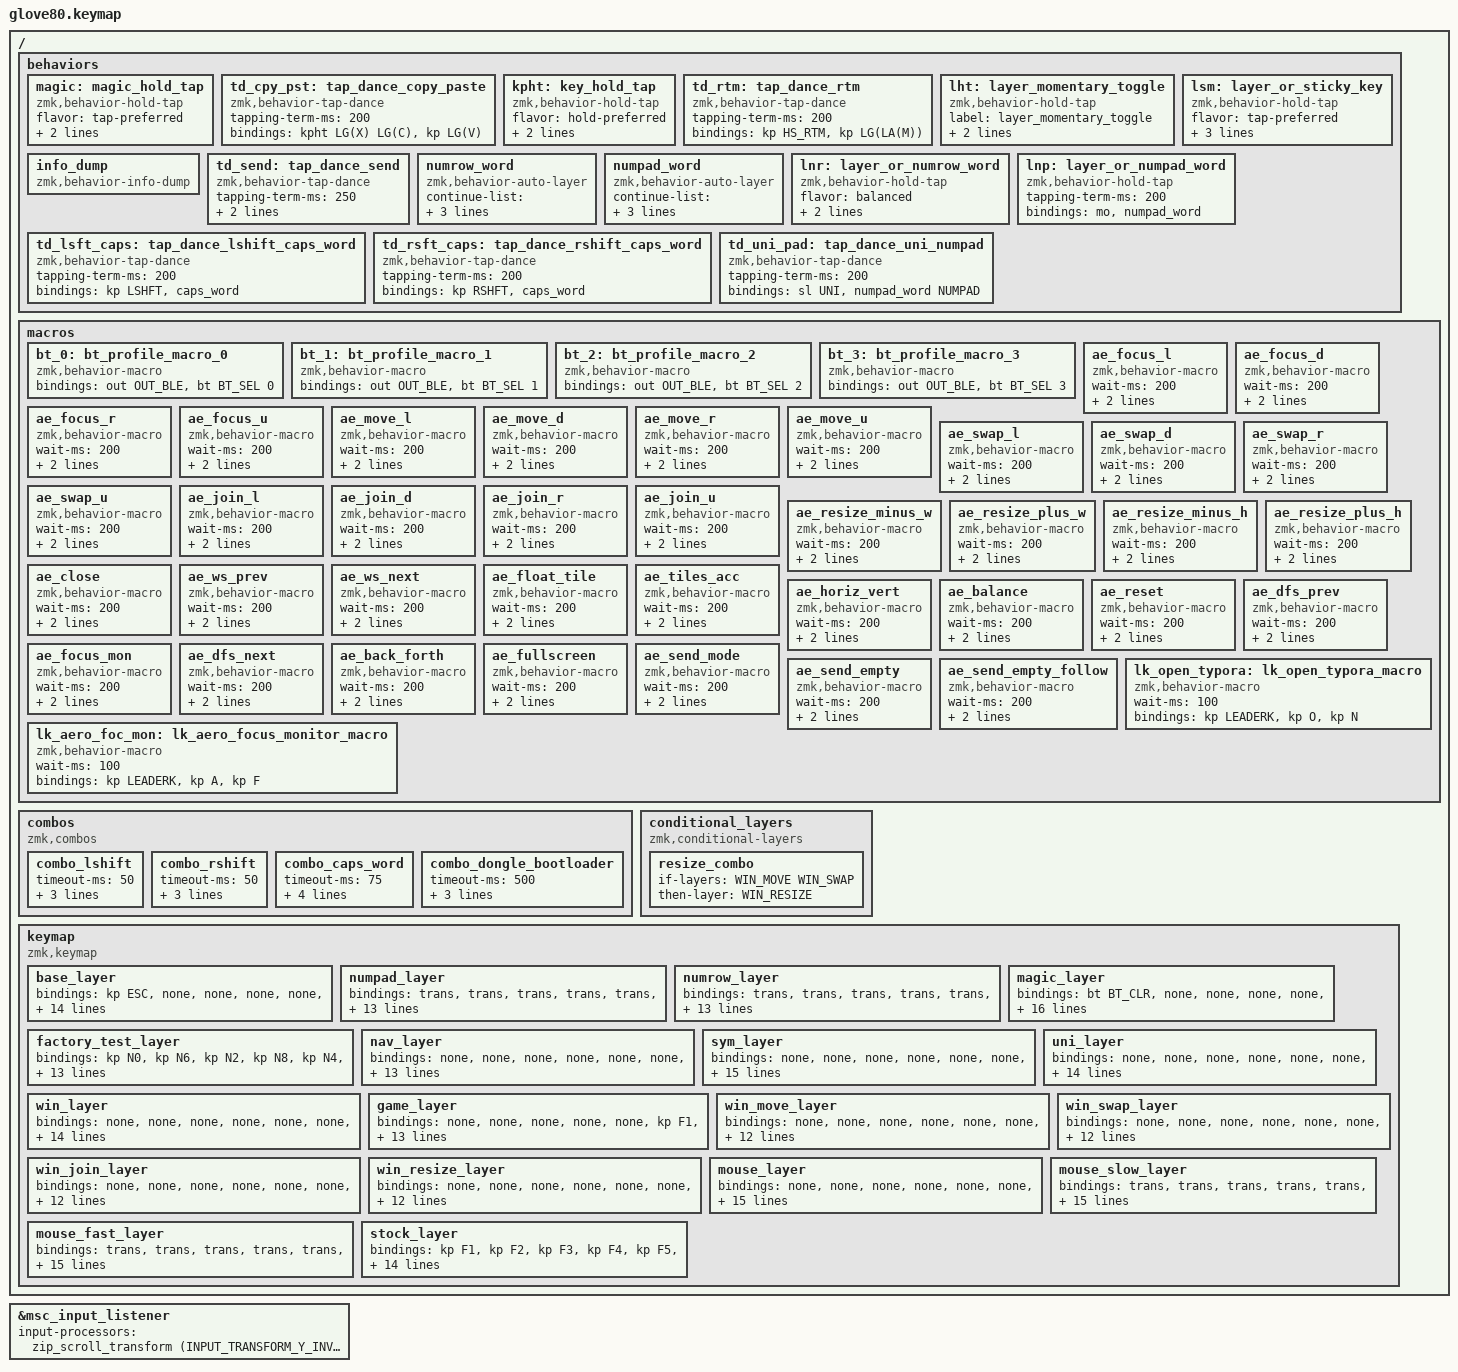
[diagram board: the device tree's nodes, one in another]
/*
 * Copyright (c) 2020 The ZMK Contributors
 *
 * SPDX-License-Identifier: MIT
 */

#include <dt-bindings/zmk/mouse.h>
#include <dt-bindings/zmk/input_transform.h>
#include <input/processors.dtsi>
#include <behaviors.dtsi>
#include <dt-bindings/zmk/bt.h>
#include <dt-bindings/zmk/keys.h>
#include <dt-bindings/zmk/outputs.h>
#include <dt-bindings/zmk/pointing.h>
#include <dt-bindings/zmk/rgb.h>

#define HYPER(X) LC(LS(LG(LA(X))))

// Layers

#define BASE         0
#define NUMPAD       1
#define NUMROW       2
#define MAGIC        3
#define TEST         4
#define NAV          5
#define SYM          6
#define UNI          7
#define WIN          8
#define GAME         9
#define WIN_MOVE     10
#define WIN_SWAP     11
#define WIN_JOIN     12
#define WIN_RESIZE   13
#define MOUSE        14
#define MOUSE_SLOW   15
#define MOUSE_FAST   16
#define STOCK        17

// Hammerspoon Hyper-key triggers (HYPER is defined in glove80.keymap)

#define HS_WARP HYPER(A) // Launch warpd
#define HS_CHRM HYPER(B) // Launch Chrome
#define HS_MEET HYPER(C) // Launch Meet
#define HS_TYPR HYPER(D) // Launch Typora
#define HS_SLAK HYPER(E) // Launch Slack
#define HS_CODE HYPER(F) // Launch VS Code
#define HS_PTAB HYPER(G) // Previous Tab
#define HS_NTAB HYPER(H) // Next Tab
#define HS_SCRN HYPER(I) // Switch Monitor Focus
#define HS_TERM HYPER(J) // Launch iTerm2
#define HS_RTM  HYPER(K) // Launch Remember the Milk
#define HS_SPFY HYPER(L) // Launch Spotify
#define HS_SCDN HYPER(M) // Scroll Down
#define HS_SCUP HYPER(N) // Scroll Up
#define HS_BTN1 HYPER(O) // Click Mouse Button 1
#define HS_MCTR HYPER(P) // Move mouse to center of screen
#define HS_MENU HYPER(Q) // Open interactive hammerspoon menu system
#define HS_TSCR HYPER(R) // Trackball scroll mode
#define LEADERK HYPER(S) // Open Leader Key
#define HS_TNEW HYPER(T) // New Tab
#define SHRTCAT HYPER(U) // Shortcat.app
#define HRCLICK HYPER(V) // Homerow.app click mode
#define HRSCRLL HYPER(W) // Homerow.app scroll mode

// Magnet.app

#define MAG_L   LC(LA(LEFT))
#define MAG_R   LC(LA(RIGHT))
#define MAG_MAX LC(LA(ENTER))
#define MAG_RST LC(LA(BSPC))

// Aerospace.app — hyper chord triggers action mode; macros append the verb key

#define AE_CHORD HYPER(SPACE)

// Mouse speed overlay macros — hold E (slow) or R (fast) while scrolling/moving

#define SCRL_UP_LO    MOVE_Y(ZMK_POINTING_DEFAULT_SCRL_VAL / 3)
#define SCRL_DOWN_LO  MOVE_Y(-(ZMK_POINTING_DEFAULT_SCRL_VAL / 3))
#define SCRL_LEFT_LO  MOVE_X(-(ZMK_POINTING_DEFAULT_SCRL_VAL / 3))
#define SCRL_RIGHT_LO MOVE_X(ZMK_POINTING_DEFAULT_SCRL_VAL / 3)
#define SCRL_UP_HI    MOVE_Y(ZMK_POINTING_DEFAULT_SCRL_VAL * 3)
#define SCRL_DOWN_HI  MOVE_Y(-(ZMK_POINTING_DEFAULT_SCRL_VAL * 3))
#define SCRL_LEFT_HI  MOVE_X(-(ZMK_POINTING_DEFAULT_SCRL_VAL * 3))
#define SCRL_RIGHT_HI MOVE_X(ZMK_POINTING_DEFAULT_SCRL_VAL * 3)
#define MOVE_UP_LO    MOVE_Y(-(ZMK_POINTING_DEFAULT_MOVE_VAL / 3))
#define MOVE_DOWN_LO  MOVE_Y(ZMK_POINTING_DEFAULT_MOVE_VAL / 3)
#define MOVE_LEFT_LO  MOVE_X(-(ZMK_POINTING_DEFAULT_MOVE_VAL / 3))
#define MOVE_RIGHT_LO MOVE_X(ZMK_POINTING_DEFAULT_MOVE_VAL / 3)
#define MOVE_UP_HI    MOVE_Y(-(ZMK_POINTING_DEFAULT_MOVE_VAL * 3))
#define MOVE_DOWN_HI  MOVE_Y(ZMK_POINTING_DEFAULT_MOVE_VAL * 3)
#define MOVE_LEFT_HI  MOVE_X(-(ZMK_POINTING_DEFAULT_MOVE_VAL * 3))
#define MOVE_RIGHT_HI MOVE_X(ZMK_POINTING_DEFAULT_MOVE_VAL * 3)

// WIN layer LH home-row hold-taps: hold=sublayer, tap=sticky mod

#define SK_PINKY lsm 0 LCTRL
#define SK_JOIN  lsm WIN_JOIN LALT
#define SK_SWAP  lsm WIN_SWAP LGUI
#define SK_MOVE  lsm WIN_MOVE LSHFT

/ {
    behaviors {
        magic: magic_hold_tap {
            compatible = "zmk,behavior-hold-tap";
            #binding-cells = <2>;
            flavor = "tap-preferred";
            tapping-term-ms = <200>;
            bindings = <&mo>, <&none>;
        };

        td_cpy_pst: tap_dance_copy_paste {
            compatible = "zmk,behavior-tap-dance";
            #binding-cells = <0>;
            tapping-term-ms = <200>;
            bindings = <&kpht LG(X) LG(C)>, <&kp LG(V)>;
        };

        kpht: key_hold_tap {
            compatible = "zmk,behavior-hold-tap";
            #binding-cells = <2>;
            flavor = "hold-preferred";
            tapping-term-ms = <500>;
            bindings = <&kp>, <&kp>;
        };

        td_rtm: tap_dance_rtm {
            compatible = "zmk,behavior-tap-dance";
            #binding-cells = <0>;
            tapping-term-ms = <200>;
            bindings = <&kp HS_RTM>, <&kp LG(LA(M))>;
        };

        lht: layer_momentary_toggle {
            compatible = "zmk,behavior-hold-tap";
            label = "layer_momentary_toggle";
            bindings = <&mo>, <&tog>;

            #binding-cells = <2>;
            tapping-term-ms = <200>;
        };

        lsm: layer_or_sticky_key {
            compatible = "zmk,behavior-hold-tap";
            #binding-cells = <2>;
            flavor = "tap-preferred";
            tapping-term-ms = <200>;
            quick-tap-ms = <100>;
            bindings = <&mo>, <&sk>;
        };

        info_dump: info_dump {
            compatible = "zmk,behavior-info-dump";
            #binding-cells = <0>;
        };

        td_send: tap_dance_send {
            compatible = "zmk,behavior-tap-dance";
            #binding-cells = <0>;
            tapping-term-ms = <250>;
            bindings =
                <&ae_send_mode>,
                <&ae_send_empty>,
                <&ae_send_empty_follow>;
        };

        // Auto-layers (urob/zmk-auto-layer): the layer stays active while typing
        // digits and the continue-list keys, and deactivates on any other keycode.
        // Tapping the trigger again also deactivates. Two instances so NUMROW and
        // NUMPAD keep independent on/off state.

        numrow_word: numrow_word {
            compatible = "zmk,behavior-auto-layer";
            #binding-cells = <1>;
            continue-list = <BSPC DEL DOT COMMA PLUS MINUS STAR FSLH EQUAL COLON>;
            ignore-numbers;
            ignore-modifiers; // home-row mods inside the layer must not end number mode
        };

        numpad_word: numpad_word {
            compatible = "zmk,behavior-auto-layer";
            #binding-cells = <1>;
            continue-list = <BSPC DEL DOT COMMA PLUS MINUS STAR FSLH EQUAL COLON>;
            ignore-numbers;
            ignore-modifiers;
        };

        // hold = momentary layer, tap = num_word. Balanced so a roll (thumb down, digit down,
        // thumb up, digit up) taps into num_word, while a key pressed and released under the
        // held thumb, or holding past the tapping term, resolves to the layer.

        lnr: layer_or_numrow_word {
            compatible = "zmk,behavior-hold-tap";
            #binding-cells = <2>;
            flavor = "balanced";
            tapping-term-ms = <200>;
            bindings = <&mo>, <&numrow_word>;
        };

        lnp: layer_or_numpad_word {
            compatible = "zmk,behavior-hold-tap";
            #binding-cells = <2>;
            tapping-term-ms = <200>;
            bindings = <&mo>, <&numpad_word>;
        };

        // Shift combos (S+D, K+L): tap/hold = shift, double tap = caps_word.
        // Tap-dances resolve immediately on interrupt and stay held while the keys are
        // down, so single-tap and held shift behave as before.

        td_lsft_caps: tap_dance_lshift_caps_word {
            compatible = "zmk,behavior-tap-dance";
            #binding-cells = <0>;
            tapping-term-ms = <200>;
            bindings = <&kp LSHFT>, <&caps_word>;
        };

        td_rsft_caps: tap_dance_rshift_caps_word {
            compatible = "zmk,behavior-tap-dance";
            #binding-cells = <0>;
            tapping-term-ms = <200>;
            bindings = <&kp RSHFT>, <&caps_word>;
        };

        // Right upper-inner thumb: tap = one-shot UNI, double tap = numpad num_word

        td_uni_pad: tap_dance_uni_numpad {
            compatible = "zmk,behavior-tap-dance";
            #binding-cells = <0>;
            tapping-term-ms = <200>;
            bindings = <&sl UNI>, <&numpad_word NUMPAD>;
        };
    };

    macros {
        bt_0: bt_profile_macro_0 {
            compatible = "zmk,behavior-macro";
            #binding-cells = <0>;
            bindings = <&out OUT_BLE &bt BT_SEL 0>;
        };

        bt_1: bt_profile_macro_1 {
            compatible = "zmk,behavior-macro";
            #binding-cells = <0>;
            bindings = <&out OUT_BLE &bt BT_SEL 1>;
        };

        bt_2: bt_profile_macro_2 {
            compatible = "zmk,behavior-macro";
            #binding-cells = <0>;
            bindings = <&out OUT_BLE &bt BT_SEL 2>;
        };

        bt_3: bt_profile_macro_3 {
            compatible = "zmk,behavior-macro";
            #binding-cells = <0>;
            bindings = <&out OUT_BLE &bt BT_SEL 3>;
        };

        // Aerospace macros — each fires AE_CHORD then the verb key

        ae_focus_l: ae_focus_l {
            compatible = "zmk,behavior-macro";
            #binding-cells = <0>;
            wait-ms = <200>;
            tap-ms = <20>;
            bindings = <&kp AE_CHORD &kp J>;
        };

        ae_focus_d: ae_focus_d {
            compatible = "zmk,behavior-macro";
            #binding-cells = <0>;
            wait-ms = <200>;
            tap-ms = <20>;
            bindings = <&kp AE_CHORD &kp K>;
        };

        ae_focus_r: ae_focus_r {
            compatible = "zmk,behavior-macro";
            #binding-cells = <0>;
            wait-ms = <200>;
            tap-ms = <20>;
            bindings = <&kp AE_CHORD &kp L>;
        };

        ae_focus_u: ae_focus_u {
            compatible = "zmk,behavior-macro";
            #binding-cells = <0>;
            wait-ms = <200>;
            tap-ms = <20>;
            bindings = <&kp AE_CHORD &kp I>;
        };

        ae_move_l: ae_move_l {
            compatible = "zmk,behavior-macro";
            #binding-cells = <0>;
            wait-ms = <200>;
            tap-ms = <20>;
            bindings = <&kp AE_CHORD &kp LS(J)>;
        };

        ae_move_d: ae_move_d {
            compatible = "zmk,behavior-macro";
            #binding-cells = <0>;
            wait-ms = <200>;
            tap-ms = <20>;
            bindings = <&kp AE_CHORD &kp LS(K)>;
        };

        ae_move_r: ae_move_r {
            compatible = "zmk,behavior-macro";
            #binding-cells = <0>;
            wait-ms = <200>;
            tap-ms = <20>;
            bindings = <&kp AE_CHORD &kp LS(L)>;
        };

        ae_move_u: ae_move_u {
            compatible = "zmk,behavior-macro";
            #binding-cells = <0>;
            wait-ms = <200>;
            tap-ms = <20>;
            bindings = <&kp AE_CHORD &kp LS(I)>;
        };

        ae_swap_l: ae_swap_l {
            compatible = "zmk,behavior-macro";
            #binding-cells = <0>;
            wait-ms = <200>;
            tap-ms = <20>;
            bindings = <&kp AE_CHORD &kp LG(J)>;
        };

        ae_swap_d: ae_swap_d {
            compatible = "zmk,behavior-macro";
            #binding-cells = <0>;
            wait-ms = <200>;
            tap-ms = <20>;
            bindings = <&kp AE_CHORD &kp LG(K)>;
        };

        ae_swap_r: ae_swap_r {
            compatible = "zmk,behavior-macro";
            #binding-cells = <0>;
            wait-ms = <200>;
            tap-ms = <20>;
            bindings = <&kp AE_CHORD &kp LG(L)>;
        };

        ae_swap_u: ae_swap_u {
            compatible = "zmk,behavior-macro";
            #binding-cells = <0>;
            wait-ms = <200>;
            tap-ms = <20>;
            bindings = <&kp AE_CHORD &kp LG(I)>;
        };

        ae_join_l: ae_join_l {
            compatible = "zmk,behavior-macro";
            #binding-cells = <0>;
            wait-ms = <200>;
            tap-ms = <20>;
            bindings = <&kp AE_CHORD &kp LA(J)>;
        };

        ae_join_d: ae_join_d {
            compatible = "zmk,behavior-macro";
            #binding-cells = <0>;
            wait-ms = <200>;
            tap-ms = <20>;
            bindings = <&kp AE_CHORD &kp LA(K)>;
        };

        ae_join_r: ae_join_r {
            compatible = "zmk,behavior-macro";
            #binding-cells = <0>;
            wait-ms = <200>;
            tap-ms = <20>;
            bindings = <&kp AE_CHORD &kp LA(L)>;
        };

        ae_join_u: ae_join_u {
            compatible = "zmk,behavior-macro";
            #binding-cells = <0>;
            wait-ms = <200>;
            tap-ms = <20>;
            bindings = <&kp AE_CHORD &kp LA(I)>;
        };

        ae_resize_minus_w: ae_resize_minus_w {
            compatible = "zmk,behavior-macro";
            #binding-cells = <0>;
            wait-ms = <200>;
            tap-ms = <20>;
            bindings = <&kp AE_CHORD &kp LG(LS(J))>;
        };

        ae_resize_plus_w: ae_resize_plus_w {
            compatible = "zmk,behavior-macro";
            #binding-cells = <0>;
            wait-ms = <200>;
            tap-ms = <20>;
            bindings = <&kp AE_CHORD &kp LG(LS(L))>;
        };

        ae_resize_minus_h: ae_resize_minus_h {
            compatible = "zmk,behavior-macro";
            #binding-cells = <0>;
            wait-ms = <200>;
            tap-ms = <20>;
            bindings = <&kp AE_CHORD &kp LG(LS(I))>;
        };

        ae_resize_plus_h: ae_resize_plus_h {
            compatible = "zmk,behavior-macro";
            #binding-cells = <0>;
            wait-ms = <200>;
            tap-ms = <20>;
            bindings = <&kp AE_CHORD &kp LG(LS(K))>;
        };

        ae_close: ae_close {
            compatible = "zmk,behavior-macro";
            #binding-cells = <0>;
            wait-ms = <200>;
            tap-ms = <20>;
            bindings = <&kp AE_CHORD &kp W>;
        };

        ae_ws_prev: ae_ws_prev {
            compatible = "zmk,behavior-macro";
            #binding-cells = <0>;
            wait-ms = <200>;
            tap-ms = <20>;
            bindings = <&kp AE_CHORD &kp U>;
        };

        ae_ws_next: ae_ws_next {
            compatible = "zmk,behavior-macro";
            #binding-cells = <0>;
            wait-ms = <200>;
            tap-ms = <20>;
            bindings = <&kp AE_CHORD &kp O>;
        };

        ae_float_tile: ae_float_tile {
            compatible = "zmk,behavior-macro";
            #binding-cells = <0>;
            wait-ms = <200>;
            tap-ms = <20>;
            bindings = <&kp AE_CHORD &kp P>;
        };

        ae_tiles_acc: ae_tiles_acc {
            compatible = "zmk,behavior-macro";
            #binding-cells = <0>;
            wait-ms = <200>;
            tap-ms = <20>;
            bindings = <&kp AE_CHORD &kp SEMI>;
        };

        ae_horiz_vert: ae_horiz_vert {
            compatible = "zmk,behavior-macro";
            #binding-cells = <0>;
            wait-ms = <200>;
            tap-ms = <20>;
            bindings = <&kp AE_CHORD &kp FSLH>;
        };

        ae_balance: ae_balance {
            compatible = "zmk,behavior-macro";
            #binding-cells = <0>;
            wait-ms = <200>;
            tap-ms = <20>;
            bindings = <&kp AE_CHORD &kp G>;
        };

        ae_reset: ae_reset {
            compatible = "zmk,behavior-macro";
            #binding-cells = <0>;
            wait-ms = <200>;
            tap-ms = <20>;
            bindings = <&kp AE_CHORD &kp B>;
        };

        ae_dfs_prev: ae_dfs_prev {
            compatible = "zmk,behavior-macro";
            #binding-cells = <0>;
            wait-ms = <200>;
            tap-ms = <20>;
            bindings = <&kp AE_CHORD &kp M>;
        };

        ae_focus_mon: ae_focus_mon {
            compatible = "zmk,behavior-macro";
            #binding-cells = <0>;
            wait-ms = <200>;
            tap-ms = <20>;
            bindings = <&kp AE_CHORD &kp H>;
        };

        ae_dfs_next: ae_dfs_next {
            compatible = "zmk,behavior-macro";
            #binding-cells = <0>;
            wait-ms = <200>;
            tap-ms = <20>;
            bindings = <&kp AE_CHORD &kp DOT>;
        };

        ae_back_forth: ae_back_forth {
            compatible = "zmk,behavior-macro";
            #binding-cells = <0>;
            wait-ms = <200>;
            tap-ms = <20>;
            bindings = <&kp AE_CHORD &kp SQT>;
        };

        ae_fullscreen: ae_fullscreen {
            compatible = "zmk,behavior-macro";
            #binding-cells = <0>;
            wait-ms = <200>;
            tap-ms = <20>;
            bindings = <&kp AE_CHORD &kp F>;
        };

        ae_send_mode: ae_send_mode {
            compatible = "zmk,behavior-macro";
            #binding-cells = <0>;
            wait-ms = <200>;
            tap-ms = <20>;
            bindings = <&kp AE_CHORD &kp Y>;
        };

        ae_send_empty: ae_send_empty {
            compatible = "zmk,behavior-macro";
            #binding-cells = <0>;
            wait-ms = <200>;
            tap-ms = <20>;
            bindings = <&kp AE_CHORD &kp LS(Y)>;
        };

        ae_send_empty_follow: ae_send_empty_follow {
            compatible = "zmk,behavior-macro";
            #binding-cells = <0>;
            wait-ms = <200>;
            tap-ms = <20>;
            bindings = <&kp AE_CHORD &kp LG(LS(Y))>;
        };

        // Leader Key sequences

        lk_aero_foc_mon: lk_aero_focus_monitor_macro {
            compatible = "zmk,behavior-macro";
            #binding-cells = <0>;
            wait-ms = <100>;
            bindings = <&kp LEADERK &kp A &kp F>;
        };

        // Open Typora

        lk_open_typora: lk_open_typora_macro {
            compatible = "zmk,behavior-macro";
            #binding-cells = <0>;
            wait-ms = <100>;
            bindings = <&kp LEADERK &kp O &kp N>;
        };
    };

    combos {
        compatible = "zmk,combos";

        combo_lshift {
            timeout-ms = <50>;
            key-positions = <36 37>;   // S + D; double tap = caps_word
            bindings = <&td_lsft_caps>;
            layers = <BASE>;
        };

        combo_rshift {
            timeout-ms = <50>;
            key-positions = <42 43>;   // K + L; double tap = caps_word
            bindings = <&td_rsft_caps>;
            layers = <BASE>;
        };

        combo_caps_word {
            timeout-ms = <75>;
            require-prior-idle-ms = <125>;
            key-positions = <36 37 42 43>;   // S + D + K + L
            bindings = <&caps_word>;
            layers = <BASE>;
        };

        combo_dongle_bootloader {
            timeout-ms = <500>;
            key-positions = <34 45>;   // MAGIC: left pinky + right pinky (both half bootloaders)
            bindings = <&bootloader>;
            layers = <MAGIC>;
        };
    };

    conditional_layers {
        compatible = "zmk,conditional-layers";

        resize_combo {
            if-layers = <WIN_MOVE WIN_SWAP>;
            then-layer = <WIN_RESIZE>;
        };
    };

    keymap {
        compatible = "zmk,keymap";

        // BASE 0

        base_layer {
            // ---------------------------------------------------------------------------------------------------------------------------------------
            // | ESC   |NONE |NONE |NONE | NONE |                                                                    | NONE |NONE |NONE | NONE | NONE |
            // | NONE  |NONE |NONE |NONE | NONE | NONE |                                                    | NONE | NONE |NONE |NONE | NONE | NONE |
            // | NONE  |  Q  |  W  |  E  |  R   |  T   |                                                    |  Y   |  U   |  I  |  O  |  P   | NONE |
            // | NONE  |  A  |  S  |  D  |  F   |  G   |                                                    |  H   |  J   |  K  |  L  |  ;   |  '   |
            // | NONE  |  Z  |  X  |  C  |  V   |  B   |WIN/NROW|MSE/TOG| NONE  |MO(MSE)| NONE  |UNI/NPAD|  N   |  M   |  ,  |  .  |  /   | NONE |
            // | MAGIC |LCTL |LALT |LGUI |LSHFT |       | MO(SYM)| MO(NAV)|NPAD/NW| NONE  | ENT   | SYM/SPC|      | RSHFT| RGUI| RALT| RCTL | NONE |
            //
            // WIN/NROW: hold = WIN, tap = NUMROW num_word.  NPAD/NW: hold = NUMPAD, tap = NUMPAD num_word.
            // UNI/NPAD: tap = one-shot UNI, double tap = NUMPAD num_word.

            bindings = <
&kp ESC         &none      &none     &none     &none                                                                                                                &none      &none      &none     &none      &none
&none           &none      &none     &none     &none      &none                                                                                              &none  &none      &none      &none     &none      &none
&none           &kp Q      &kp W     &kp E     &kp R      &kp T                                                                                              &kp Y  &kp U      &kp I      &kp O     &kp P      &none
&caps_word      &kp A      &kp S     &kp D     &kp F      &kp G                                                                                              &kp H  &kp J      &kp K      &kp L     &kp SEMI   &kp SQT
&none           &kp Z      &kp X     &kp C     &kp V      &kp B  &lnr WIN NUMROW  &lht MOUSE MOUSE  &none               &mo MOUSE  &none      &td_uni_pad    &kp N  &kp M      &kp COMMA  &kp DOT   &kp FSLH   &none
&magic MAGIC 0  &kp LCTRL  &kp LALT  &kp LGUI  &kp LSHFT         &mo SYM          &mo NAV           &lnp NUMPAD NUMPAD  &none      &kp ENTER  &lt SYM SPACE         &kp RSHFT  &kp RGUI   &kp RALT  &kp RCTRL  &none
            >;
        };

        // NUMPAD 1

        numpad_layer {
            // NUMPAD: 10-key grid shifted up one row, 0 on upper-inner right thumb.
            // 7 8 9 on the number-row keys, 4 5 6 on U I O, 1 2 3 on J K L, minus on P, slash on ;.
            // &trans fill is deliberate: num_word only ends on real keycodes, so non-grid keys must
            // fall through. Period/comma fall through to their own keys; Space, Enter, or any letter
            // ends the mode. Entered from L_T6 (hold/tap) or double-tap on R_T1.

            bindings = <
&trans  &trans  &trans  &trans  &trans                                                                  &trans  &trans  &trans  &trans     &trans
&trans  &trans  &trans  &trans  &trans  &trans                                                  &trans  &kp N7  &kp N8  &kp N9  &trans     &trans
&trans  &trans  &trans  &trans  &trans  &trans                                                  &trans  &kp N4  &kp N5  &kp N6  &kp MINUS  &trans
&trans  &trans  &trans  &trans  &trans  &trans                                                  &trans  &kp N1  &kp N2  &kp N3  &kp FSLH   &trans
&trans  &trans  &trans  &trans  &trans  &trans  &trans  &trans  &trans  &trans  &trans  &kp N0  &trans  &trans  &trans  &trans  &trans     &trans
&trans  &trans  &trans  &trans  &trans          &trans  &trans  &trans  &trans  &trans  &trans          &trans  &trans  &trans  &trans     &trans
            >;
        };

        // NUMROW 2

        numrow_layer {
            // NUMROW: number-row digits one row down (Q..P = 1..0, minus right of P), same finger per digit.
            // The BASE number row is disabled; this layer and NUMPAD are the only digit sources.
            // Bottom-row mods on both hands fall through and do not end number mode (ignore-modifiers).
            // Entered by tapping WIN (num_word); ends on the first non-digit key.
            // Left home row = mods, so shift+digit (or SYM) gives the symbols.
            // &trans fill is deliberate (see NUMPAD).

            bindings = <
&trans  &trans     &trans    &trans    &trans                                                                     &trans  &trans  &trans  &trans  &trans
&trans  &trans     &trans    &trans    &trans     &trans                                                  &trans  &trans  &trans  &trans  &trans  &trans
&trans  &kp N1     &kp N2    &kp N3    &kp N4     &kp N5                                                  &kp N6  &kp N7  &kp N8  &kp N9  &kp N0  &kp MINUS
&trans  &kp LCTRL  &kp LALT  &kp LGUI  &kp LSHFT  &trans                                                  &trans  &trans  &trans  &trans  &trans  &trans
&trans  &trans     &trans    &trans    &trans     &trans  &trans  &trans  &trans  &trans  &trans  &trans  &trans  &trans  &trans  &trans  &trans  &trans
&trans  &trans     &trans    &trans    &trans             &trans  &trans  &trans  &trans  &trans  &trans          &trans  &trans  &trans  &trans  &trans
            >;
        };

        // MAGIC 3

        magic_layer {
            bindings = <
&bt BT_CLR   &none            &none            &none            &none                                                                                          &none     &none  &none  &none      &bt BT_CLR_ALL
&none        &none            &none            &none            &none            &none                                                                  &none  &none     &none  &none  &none      &none
&none        &rgb_ug RGB_SPI  &rgb_ug RGB_SAI  &rgb_ug RGB_HUI  &rgb_ug RGB_BRI  &rgb_ug RGB_TOG                                                        &none  &none     &none  &none  &none      &none
&bootloader  &rgb_ug RGB_SPD  &rgb_ug RGB_SAD  &rgb_ug RGB_HUD  &rgb_ug RGB_BRD  &rgb_ug RGB_EFF                                                        &none  &none     &none  &none  &none      &bootloader
&sys_reset   &none            &none            &none            &none            &none            &bt_2  &bt_3  &none         &none  &none       &none  &none  &none     &none  &none  &none      &sys_reset
&none        &none            &none            &none            &none                             &bt_0  &bt_1  &out OUT_USB  &none  &info_dump  &none         &to GAME  &none  &none  &to STOCK  &to TEST
            >;
        };

        // TEST 4

        factory_test_layer {
            bindings = <
&kp N0  &kp N6  &kp N2  &kp N8  &kp N4                                                                  &kp N4  &kp N8  &kp N2  &kp N6  &kp N0
&kp N1  &kp N7  &kp N3  &kp N9  &kp N5  &kp N0                                                  &kp N0  &kp N5  &kp N9  &kp N3  &kp N7  &kp N1
&kp N2  &kp N8  &kp N4  &kp N0  &kp N6  &kp N1                                                  &kp N1  &kp N6  &kp N0  &kp N4  &kp N8  &kp N2
&kp N3  &kp N9  &kp N5  &kp N1  &kp N7  &kp N2                                                  &kp N2  &kp N7  &kp N1  &kp N5  &kp N9  &kp N3
&kp N4  &kp N0  &kp N6  &kp N2  &kp N8  &kp N3  &kp N4  &kp N5  &kp N6  &kp N6  &kp N5  &kp N4  &kp N3  &kp N8  &kp N2  &kp N6  &kp N0  &kp N4
&kp N5  &kp N1  &kp N7  &kp N3  &kp N9          &kp N7  &kp N8  &kp N9  &kp N9  &kp N8  &kp N7          &kp N9  &kp N3  &kp N7  &kp N1  &kp N5
            >;
        };

        // NAV 5

        nav_layer {
            // NAV: HJKL arrows, home row mods on left, nav cluster on right bottom alpha

            bindings = <
&none   &none      &none     &none     &none                                                                          &none        &none        &none        &none        &none
&none   &none      &none     &none     &none      &none                                                     &none     &none        &none        &none        &none        &none
&none   &none      &none     &none     &none      &none                                                     &none     &kp HS_PTAB  &none        &kp HS_NTAB  &none        &none
&none   &kp LCTRL  &kp LALT  &kp LGUI  &kp LSHFT  &none                                                     &kp LEFT  &kp DOWN     &kp UP       &kp RIGHT    &none        &none
&none   &none      &none     &none     &none      &none  &none  &none   &none  &none  &none          &none  &kp HOME  &kp PG_DN    &kp PG_UP    &kp END      &none        &none
&trans  &none      &none     &none     &none             &none  &trans  &none  &none  &kp LS(ENTER)  &none            &kp HS_SCDN  &kp HS_SCUP  &kp HS_BTN1  &kp HS_MCTR  &none
            >;
        };

        // SYM 6

        sym_layer {
            // SYM: symbols on left alpha, parens/brackets on right, mods on left home row

            bindings = <
&none   &none      &none     &none        &none                                                                                  &none     &none      &none     &none             &none
&none   &none      &none     &none        &none      &none                                                            &kp CARET  &kp AMPS  &kp ASTRK  &none     &none             &none
&none   &kp EXCL   &kp AT    &kp HASH     &kp DLLR   &kp PRCNT                                                        &kp ESC    &kp LBRC  &kp TAB    &kp RBRC  &kp SINGLE_QUOTE  &none
&none   &kp LCTRL  &kp LALT  &kp LGUI     &kp LSHFT  &kp EQUAL                                                        &kp PIPE   &kp LPAR  &kp MINUS  &kp RPAR  &kp COLON         &kp DQT
&none   &kp BSLH   &kp LT    &td_cpy_pst  &kp GT     &none      &none   &none  &none  &none  &kp DEL        &none     &kp GRAVE  &kp LBKT  &kp UNDER  &kp RBKT  &kp QMARK         &none
&trans  &trans     &trans    &trans       &trans                &trans  &none  &none  &none  &kp LG(ENTER)  &kp BSPC             &trans    &trans     &trans    &trans            &none
            >;
        };

        // UNI 7

        uni_layer {
            // UNI: app launchers via Hammerspoon, media, Magnet

            bindings = <
&none   &none      &none     &none        &none                                                                               &none        &none            &none        &none        &none
&none   &none      &none     &none        &none      &none                                                       &none        &none        &none            &none        &none        &none
&none   &none      &none     &kp HS_MENU  &none      &none                                                       &kp HS_CHRM  &kp HS_MEET  &lk_open_typora  &kp HS_SLAK  &kp HS_CODE  &kp HS_TERM
&none   &sk LCTRL  &sk LALT  &sk LGUI     &sk LSHFT  &none                                                       &td_rtm      &kp C_PREV   &kp C_PP         &kp C_NEXT   &kp HS_SPFY  &none
&none   &none      &none     &none        &none      &kp LC(B)  &kp HS_MENU  &none  &none  &none  &none  &trans  &none        &kp MAG_L    &kp MAG_MAX      &kp MAG_R    &kp MAG_RST  &none
&trans  &none      &none     &none        &none                 &none        &none  &none  &none  &none  &none                &none        &none            &none        &none        &none
            >;
        };

        // WIN 8

        win_layer {
            // WIN: Aerospace window management via AE_CHORD + verb dispatch

            bindings = <
&none  &none      &none      &none     &none                                                                                          &none         &none        &none         &none           &none
&none  &none      &none      &none     &none     &none                                                                 &none          &none         &none        &none         &none           &none
&none  &none      &ae_close  &none     &none     &none                                                                 &td_send       &ae_ws_prev   &ae_focus_u  &ae_ws_next   &ae_float_tile  &none
&none  &SK_PINKY  &SK_JOIN   &SK_SWAP  &SK_MOVE  &ae_balance                                                           &ae_focus_mon  &ae_focus_l   &ae_focus_d  &ae_focus_r   &ae_tiles_acc   &ae_back_forth
&none  &none      &none      &none     &none     &ae_reset    &none  &none  &none  &none  &none           &none        &none          &ae_dfs_prev  &none        &ae_dfs_next  &ae_horiz_vert  &none
&none  &none      &none      &none     &none                  &none  &none  &none  &none  &ae_fullscreen  &kp LEADERK                 &none         &none        &none         &none           &none
            >;
        };

        // GAME 9

        game_layer {
            // GAME: WASD game friendly layout

            bindings = <
&none      &none      &none   &none   &none                                                                               &kp F1  &kp F2     &kp F3    &kp F4    &kp F5
&kp GRAVE  &kp N6     &kp N7  &kp N8  &kp N9  &kp N0                                                              &kp F6  &kp F7  &kp F8     &kp F9    &kp F10   &kp MINUS
&kp T      &kp N1     &kp N2  &kp N3  &kp N4  &kp N5                                                              &kp Y   &kp U   &kp I      &kp O     &kp P     &none
&kp G      &kp TAB    &kp Q   &kp W   &kp E   &kp R                                                               &kp H   &kp J   &kp K      &kp L     &kp SEMI  &kp SQT
&kp B      &kp LSHFT  &kp A   &kp S   &kp D   &kp F   &none      &none      &none  &none     &kp UP    &none      &kp N   &kp M   &kp COMMA  &kp DOT   &kp FSLH  &none
&kp V      &kp LCTRL  &kp Z   &kp X   &kp C           &kp SPACE  &kp LCTRL  &none  &kp LEFT  &kp DOWN  &kp RIGHT          &none   &none      &kp LBKT  &kp RBKT  &to BASE
            >;
        };

        // WIN_MOVE 10

        win_move_layer {
            bindings = <
&none  &none   &none   &none   &none                                                           &none       &none       &none       &none  &none
&none  &none   &none   &none   &none   &none                                            &none  &none       &none       &none       &none  &none
&none  &none   &none   &none   &none   &none                                            &none  &none       &ae_move_u  &none       &none  &none
&none  &trans  &trans  &trans  &trans  &none                                            &none  &ae_move_l  &ae_move_d  &ae_move_r  &none  &none
&none  &none   &none   &none   &none   &none  &none  &none  &none  &none  &none  &none  &none  &none       &none       &none       &none  &none
&none  &none   &none   &none   &none          &none  &none  &none  &none  &none  &none         &none       &none       &none       &none  &none
            >;
        };

        // WIN_SWAP 11

        win_swap_layer {
            bindings = <
&none  &none   &none   &none   &none                                                           &none       &none       &none       &none  &none
&none  &none   &none   &none   &none   &none                                            &none  &none       &none       &none       &none  &none
&none  &none   &none   &none   &none   &none                                            &none  &none       &ae_swap_u  &none       &none  &none
&none  &trans  &trans  &trans  &trans  &none                                            &none  &ae_swap_l  &ae_swap_d  &ae_swap_r  &none  &none
&none  &none   &none   &none   &none   &none  &none  &none  &none  &none  &none  &none  &none  &none       &none       &none       &none  &none
&none  &none   &none   &none   &none          &none  &none  &none  &none  &none  &none         &none       &none       &none       &none  &none
            >;
        };

        // WIN_JOIN 12

        win_join_layer {
            bindings = <
&none  &none   &none   &none   &none                                                           &none       &none       &none       &none  &none
&none  &none   &none   &none   &none   &none                                            &none  &none       &none       &none       &none  &none
&none  &none   &none   &none   &none   &none                                            &none  &none       &ae_join_u  &none       &none  &none
&none  &trans  &trans  &trans  &trans  &none                                            &none  &ae_join_l  &ae_join_d  &ae_join_r  &none  &none
&none  &none   &none   &none   &none   &none  &none  &none  &none  &none  &none  &none  &none  &none       &none       &none       &none  &none
&none  &none   &none   &none   &none          &none  &none  &none  &none  &none  &none         &none       &none       &none       &none  &none
            >;
        };

        // WIN_RESIZE 13

        win_resize_layer {
            bindings = <
&none  &none   &none   &none   &none                                                           &none               &none               &none              &none  &none
&none  &none   &none   &none   &none   &none                                            &none  &none               &none               &none              &none  &none
&none  &none   &none   &none   &none   &none                                            &none  &none               &ae_resize_minus_h  &none              &none  &none
&none  &trans  &trans  &trans  &trans  &none                                            &none  &ae_resize_minus_w  &ae_resize_plus_h   &ae_resize_plus_w  &none  &none
&none  &none   &none   &none   &none   &none  &none  &none  &none  &none  &none  &none  &none  &none               &none               &none              &none  &none
&none  &none   &none   &none   &none          &none  &none  &none  &none  &none  &none         &none               &none               &none              &none  &none
            >;
        };

        // MOUSE 14

        mouse_layer {
            // hjkl = scroll, 8/uio = cursor move (inverted-T), xcv = right/mid/left click (left hand), SYM=trackball scroll mode, m/,/. = left/right/middle click, n=MB4 (back), /=MB5 (forward)

            bindings = <
&none  &none      &none     &none           &none                                                                                   &none           &none           &none            &none     &none
&none  &none      &none     &none           &none           &none                                                   &none           &none           &mmv MOVE_UP    &none            &none     &none
&none  &none      &none     &mo MOUSE_SLOW  &mo MOUSE_FAST  &none                                                   &none           &mmv MOVE_LEFT  &mmv MOVE_DOWN  &mmv MOVE_RIGHT  &none     &none
&none  &kp LCTRL  &kp LALT  &kp LGUI        &kp LSHFT       &none                                                   &msc SCRL_LEFT  &msc SCRL_DOWN  &msc SCRL_UP    &msc SCRL_RIGHT  &none     &none
&none  &none      &mkp MB2  &mkp MB3        &mkp MB1        &none  &none        &trans  &none  &none  &none  &none  &mkp MB4        &mkp MB1        &mkp MB3        &mkp MB2         &mkp MB5  &none
&none  &kp LCTRL  &kp LALT  &kp LGUI        &kp LSHFT              &kp HS_TSCR  &none   &none  &none  &none  &none                  &none           &none           &none            &none     &none
            >;
        };

        // MOUSE_SLOW 15

        mouse_slow_layer {
            // hold Q while scrolling/moving for precision speed
            bindings = <
&trans  &trans  &trans  &trans  &trans                                                                             &trans             &trans             &trans              &trans  &trans
&trans  &trans  &trans  &trans  &trans  &trans                                                  &trans             &trans             &mmv MOVE_UP_LO    &trans              &trans  &trans
&trans  &trans  &trans  &trans  &trans  &trans                                                  &trans             &mmv MOVE_LEFT_LO  &mmv MOVE_DOWN_LO  &mmv MOVE_RIGHT_LO  &trans  &trans
&trans  &trans  &trans  &trans  &trans  &trans                                                  &msc SCRL_LEFT_LO  &msc SCRL_DOWN_LO  &msc SCRL_UP_LO    &msc SCRL_RIGHT_LO  &trans  &trans
&trans  &trans  &trans  &trans  &trans  &trans  &trans  &trans  &trans  &trans  &trans  &trans  &trans             &trans             &trans             &trans              &trans  &trans
&trans  &trans  &trans  &trans  &trans          &trans  &trans  &trans  &trans  &trans  &trans                     &trans             &trans             &trans              &trans  &trans
            >;
        };

        // MOUSE_FAST 16

        mouse_fast_layer {
            // hold R while scrolling/moving for turbo speed
            bindings = <
&trans  &trans  &trans  &trans  &trans                                                                             &trans             &trans             &trans              &trans  &trans
&trans  &trans  &trans  &trans  &trans  &trans                                                  &trans             &trans             &mmv MOVE_UP_HI    &trans              &trans  &trans
&trans  &trans  &trans  &trans  &trans  &trans                                                  &trans             &mmv MOVE_LEFT_HI  &mmv MOVE_DOWN_HI  &mmv MOVE_RIGHT_HI  &trans  &trans
&trans  &trans  &trans  &trans  &trans  &trans                                                  &msc SCRL_LEFT_HI  &msc SCRL_DOWN_HI  &msc SCRL_UP_HI    &msc SCRL_RIGHT_HI  &trans  &trans
&trans  &trans  &trans  &trans  &trans  &trans  &trans  &trans  &trans  &trans  &trans  &trans  &trans             &trans             &trans             &trans              &trans  &trans
&trans  &trans  &trans  &trans  &trans          &trans  &trans  &trans  &trans  &trans  &trans                     &trans             &trans             &trans              &trans  &trans
            >;
        };

        // STOCK 17

        stock_layer {
            // STOCK: default Glove80 keycap layout for guest use; magic key exits back to BASE

            bindings = <
&kp F1     &kp F2    &kp F3   &kp F4    &kp F5                                                                                     &kp F6  &kp F7     &kp F8    &kp F9    &kp F10
&kp EQUAL  &kp N1    &kp N2   &kp N3    &kp N4     &kp N5                                                                  &kp N6  &kp N7  &kp N8     &kp N9    &kp N0    &kp MINUS
&kp TAB    &kp Q     &kp W    &kp E     &kp R      &kp T                                                                   &kp Y   &kp U   &kp I      &kp O     &kp P     &kp BSLH
&kp ESC    &kp A     &kp S    &kp D     &kp F      &kp G                                                                   &kp H   &kp J   &kp K      &kp L     &kp SEMI  &kp SQT
&kp GRAVE  &kp Z     &kp X    &kp C     &kp V      &kp B   &kp LSHFT  &kp LCTRL  &none     &kp LGUI  &kp RCTRL  &kp RSHFT  &kp N   &kp M   &kp COMMA  &kp DOT   &kp FSLH  &kp PG_UP
&to BASE   &kp HOME  &kp END  &kp LEFT  &kp RIGHT          &kp BSPC   &kp DEL    &kp LALT  &kp RALT  &kp RET    &kp SPACE          &kp UP  &kp DOWN   &kp LBKT  &kp RBKT  &kp PG_DN
            >;
        };
    };
};

&msc_input_listener { input-processors = <&zip_scroll_transform (INPUT_TRANSFORM_Y_INVERT | INPUT_TRANSFORM_X_INVERT)>; };
